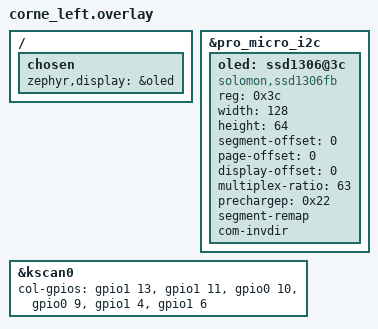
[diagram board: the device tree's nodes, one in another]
#include "corne.dtsi"

&pro_micro_i2c {
    status = "okay";

    oled: ssd1306@3c {
        compatible = "solomon,ssd1306fb";
        reg = <0x3c>;
        width = <128>;
        height = <64>;
        segment-offset = <0>;
        page-offset = <0>;
        display-offset = <0>;
        multiplex-ratio = <63>;
        prechargep = <0x22>;
        segment-remap;
        com-invdir;
    };
};

/ {
    chosen {
        zephyr,display = &oled;
    };
};

&kscan0 {
    col-gpios = <&gpio1 13 GPIO_ACTIVE_HIGH>,
                <&gpio1 11 GPIO_ACTIVE_HIGH>,
                <&gpio0 10 GPIO_ACTIVE_HIGH>,
                <&gpio0 9 GPIO_ACTIVE_HIGH>,
                <&gpio1 4 GPIO_ACTIVE_HIGH>,
                <&gpio1 6 GPIO_ACTIVE_HIGH>;
};

